VERSION "created by canmatrix"

NS_ :

BS_:

BU_: Boening

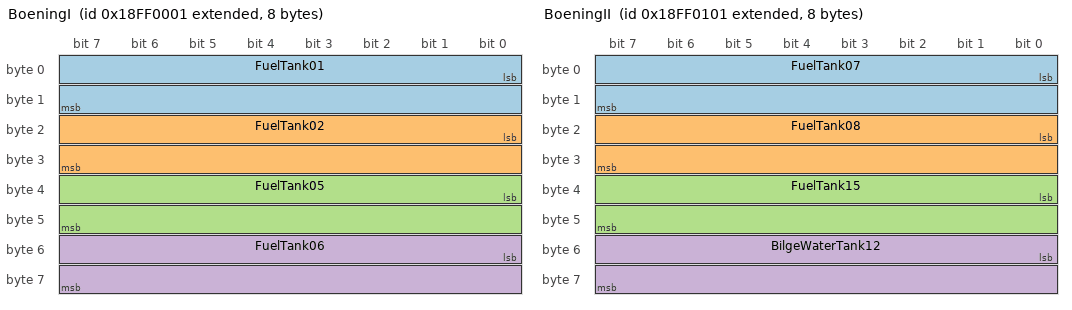
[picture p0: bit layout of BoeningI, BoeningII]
BO_ 2566848513 BoeningI: 8 Vector__XXX
 SG_ FuelTank01 : 0|16@1+ (1,0) [0|65535] "L" Vector__XXX
 SG_ FuelTank02 : 16|16@1+ (1,0) [0|65535] "L" Vector__XXX
 SG_ FuelTank05 : 32|16@1+ (1,0) [0|65535] "L" Vector__XXX
 SG_ FuelTank06 : 48|16@1+ (1,0) [0|65535] "L" Vector__XXX

BO_ 2566848769 BoeningII: 8 Vector__XXX
 SG_ FuelTank07 : 0|16@1+ (1,0) [0|65535] "L" Vector__XXX
 SG_ FuelTank08 : 16|16@1+ (1,0) [0|65535] "L" Vector__XXX
 SG_ FuelTank15 : 32|16@1+ (1,0) [0|65535] "L" Vector__XXX
 SG_ BilgeWaterTank12 : 48|16@1+ (1,0) [0|65535] "L" Vector__XXX

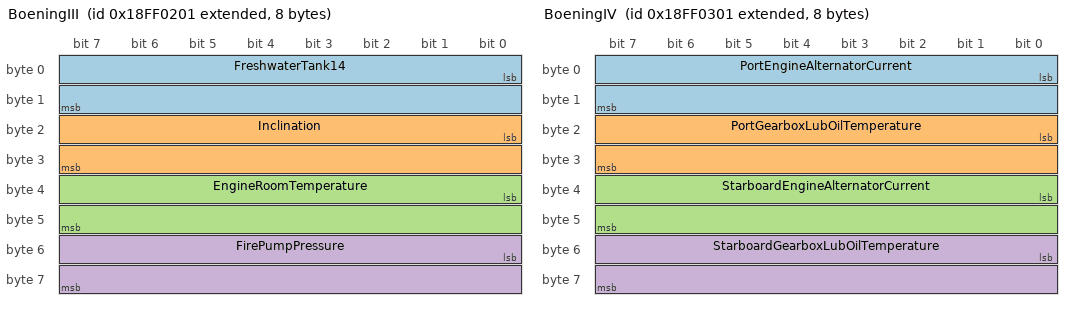
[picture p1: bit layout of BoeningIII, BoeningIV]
BO_ 2566849025 BoeningIII: 8 Vector__XXX
 SG_ FreshwaterTank14 : 0|16@1+ (1,0) [0|65535] "L" Vector__XXX
 SG_ Inclination : 16|16@1- (1,0) [-32768|32767] "grad" Vector__XXX
 SG_ EngineRoomTemperature : 32|16@1+ (1,0) [0|65535] "grad Celsius" Vector__XXX
 SG_ FirePumpPressure : 48|16@1+ (0.1,0) [0|6553.5] "bar" Vector__XXX

BO_ 2566849281 BoeningIV: 8 Vector__XXX
 SG_ PortEngineAlternatorCurrent : 0|16@1+ (1,0) [0|65535] "A" Vector__XXX
 SG_ PortGearboxLubOilTemperature : 16|16@1+ (1,0) [0|65535] "grad Celsius" Vector__XXX
 SG_ StarboardEngineAlternatorCurrent : 32|16@1+ (1,0) [0|65535] "A" Vector__XXX
 SG_ StarboardGearboxLubOilTemperature : 48|16@1+ (1,0) [0|65535] "grad Celsius" Vector__XXX

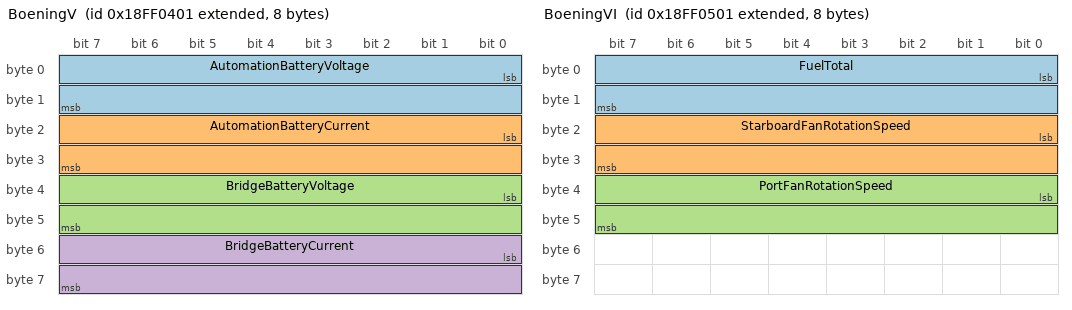
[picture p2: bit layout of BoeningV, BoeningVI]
BO_ 2566849537 BoeningV: 8 Vector__XXX
 SG_ AutomationBatteryVoltage : 0|16@1- (0.1,0) [-3276.8|3276.7] "V" Vector__XXX
 SG_ AutomationBatteryCurrent : 16|16@1- (0.1,0) [-3276.8|3276.7] "A" Vector__XXX
 SG_ BridgeBatteryVoltage : 32|16@1- (0.1,0) [-3276.8|3276.7] "V" Vector__XXX
 SG_ BridgeBatteryCurrent : 48|16@1- (0.1,0) [-3276.8|3276.7] "A" Vector__XXX

BO_ 2566849793 BoeningVI: 8 Vector__XXX
 SG_ FuelTotal : 0|16@1+ (1,0) [0|65535] "L" Vector__XXX
 SG_ StarboardFanRotationSpeed : 16|16@1+ (1,0) [0|65535] "1/min" Vector__XXX
 SG_ PortFanRotationSpeed : 32|16@1+ (1,0) [0|65535] "%" Vector__XXX

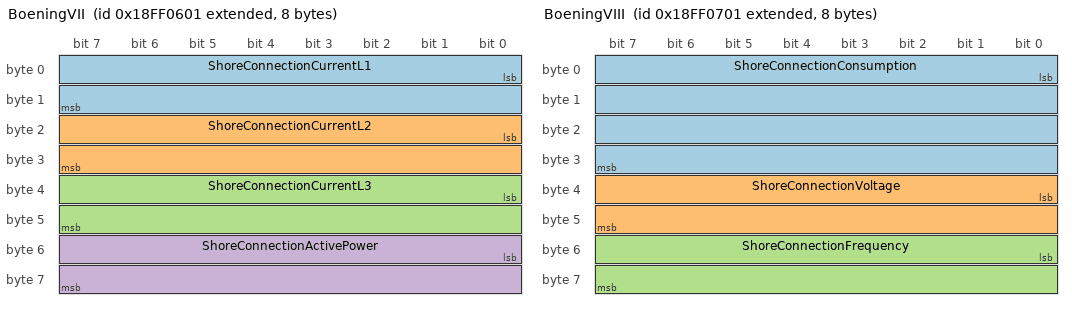
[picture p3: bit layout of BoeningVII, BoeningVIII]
BO_ 2566850049 BoeningVII: 8 Vector__XXX
 SG_ ShoreConnectionCurrentL1 : 0|16@1+ (0.1,0) [0|6553.5] "A" Vector__XXX
 SG_ ShoreConnectionCurrentL2 : 16|16@1+ (0.1,0) [0|6553.5] "A" Vector__XXX
 SG_ ShoreConnectionCurrentL3 : 32|16@1+ (0.1,0) [0|6553.5] "A" Vector__XXX
 SG_ ShoreConnectionActivePower : 48|16@1+ (1,0) [0|65535] "kW" Vector__XXX

BO_ 2566850305 BoeningVIII: 8 Vector__XXX
 SG_ ShoreConnectionConsumption : 0|32@1+ (1,0) [0|4294967295] "kWh" Vector__XXX
 SG_ ShoreConnectionVoltage : 32|16@1+ (1,0) [0|65535] "V" Vector__XXX
 SG_ ShoreConnectionFrequency : 48|16@1+ (0.1,0) [0|6553.5] "Hz" Vector__XXX

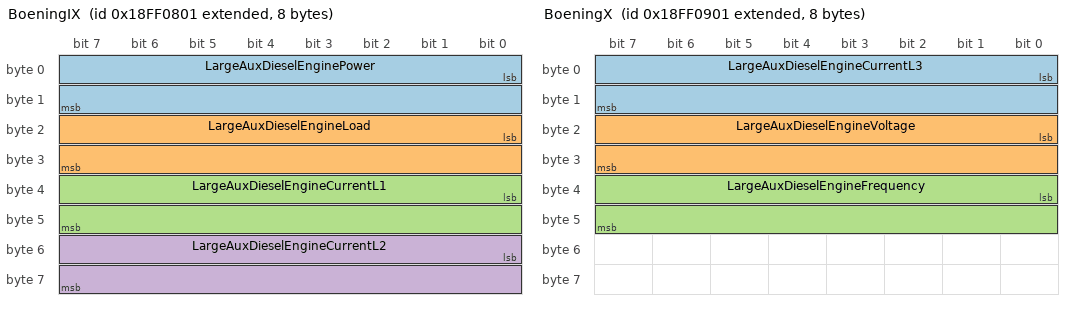
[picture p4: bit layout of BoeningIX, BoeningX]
BO_ 2566850561 BoeningIX: 8 Vector__XXX
 SG_ LargeAuxDieselEnginePower : 0|16@1+ (1,0) [0|65535] "kW" Vector__XXX
 SG_ LargeAuxDieselEngineLoad : 16|16@1+ (1,0) [0|65535] "%" Vector__XXX
 SG_ LargeAuxDieselEngineCurrentL1 : 32|16@1+ (0.1,0) [0|6553.5] "A" Vector__XXX
 SG_ LargeAuxDieselEngineCurrentL2 : 48|16@1+ (0.1,0) [0|6553.5] "A" Vector__XXX

BO_ 2566850817 BoeningX: 8 Vector__XXX
 SG_ LargeAuxDieselEngineCurrentL3 : 0|16@1+ (0.1,0) [0|6553.5] "A" Vector__XXX
 SG_ LargeAuxDieselEngineVoltage : 16|16@1+ (1,0) [0|65535] "V" Vector__XXX
 SG_ LargeAuxDieselEngineFrequency : 32|16@1+ (0.1,0) [0|6553.5] "Hz" Vector__XXX

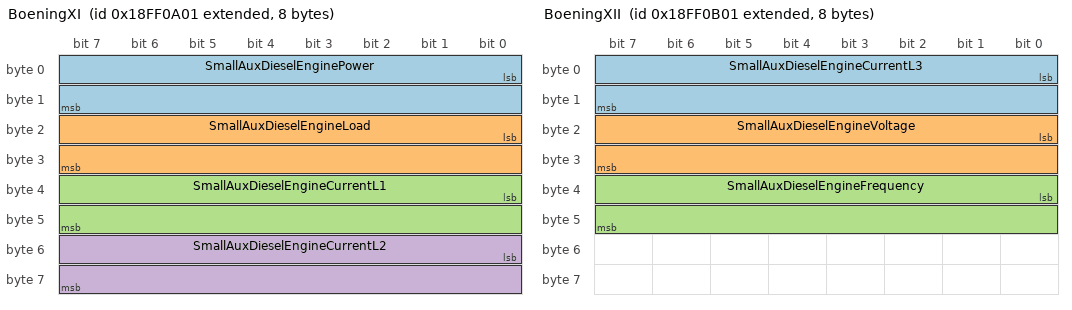
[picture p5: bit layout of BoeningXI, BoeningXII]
BO_ 2566851073 BoeningXI: 8 Vector__XXX
 SG_ SmallAuxDieselEnginePower : 0|16@1+ (1,0) [0|65535] "kW" Vector__XXX
 SG_ SmallAuxDieselEngineLoad : 16|16@1+ (1,0) [0|65535] "%" Vector__XXX
 SG_ SmallAuxDieselEngineCurrentL1 : 32|16@1+ (0.1,0) [0|6553.5] "A" Vector__XXX
 SG_ SmallAuxDieselEngineCurrentL2 : 48|16@1+ (0.1,0) [0|6553.5] "A" Vector__XXX

BO_ 2566851329 BoeningXII: 8 Vector__XXX
 SG_ SmallAuxDieselEngineCurrentL3 : 0|16@1+ (0.1,0) [0|6553.5] "A" Vector__XXX
 SG_ SmallAuxDieselEngineVoltage : 16|16@1+ (1,0) [0|65535] "V" Vector__XXX
 SG_ SmallAuxDieselEngineFrequency : 32|16@1+ (0.1,0) [0|6553.5] "Hz" Vector__XXX

BO_ 2566851585 BoeningXIII: 8 Vector__XXX
 SG_ SmallAuxDieselEngineLubOilPressure : 0|16@1+ (0.1,0) [0|6553.5] "bar" Vector__XXX
 SG_ SmallAuxDieselEngineCoolWaterTemperature : 16|16@1+ (1,0) [0|65535] "grad Celsius" Vector__XXX

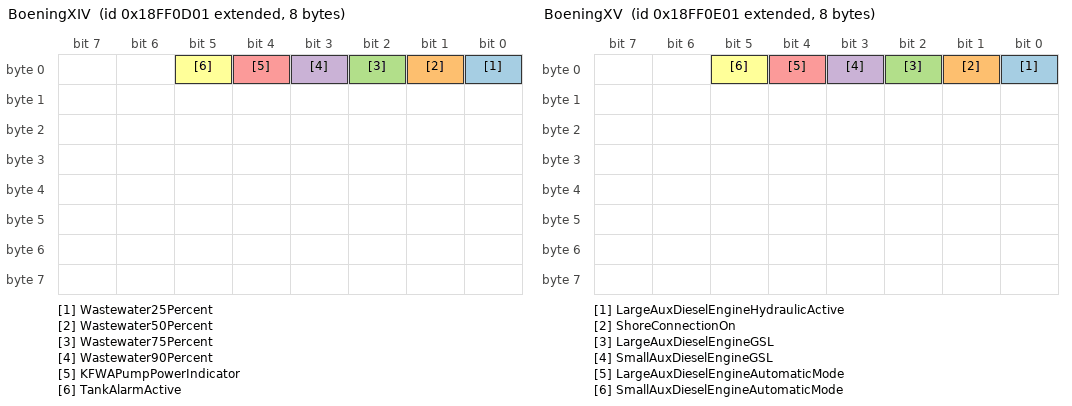
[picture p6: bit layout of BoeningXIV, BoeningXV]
BO_ 2566851841 BoeningXIV: 8 Vector__XXX
 SG_ Wastewater25Percent : 0|1@1+ (1,0) [0|1] "aus/an" Vector__XXX
 SG_ Wastewater50Percent : 1|1@1+ (1,0) [0|1] "aus/an" Vector__XXX
 SG_ Wastewater75Percent : 2|1@1+ (1,0) [0|1] "aus/an" Vector__XXX
 SG_ Wastewater90Percent : 3|1@1+ (1,0) [0|1] "aus/an" Vector__XXX
 SG_ KFWAPumpPowerIndicator : 4|1@1+ (1,0) [0|1] "aus/an" Vector__XXX
 SG_ TankAlarmActive : 5|1@1+ (1,0) [0|1] "aus/an" Vector__XXX

BO_ 2566852097 BoeningXV: 8 Vector__XXX
 SG_ LargeAuxDieselEngineHydraulicActive : 0|1@1+ (1,0) [0|1] "aus/an" Vector__XXX
 SG_ ShoreConnectionOn : 1|1@1+ (1,0) [0|1] "aus/an" Vector__XXX
 SG_ LargeAuxDieselEngineGSL : 2|1@1+ (1,0) [0|1] "aus/an" Vector__XXX
 SG_ SmallAuxDieselEngineGSL : 3|1@1+ (1,0) [0|1] "aus/an" Vector__XXX
 SG_ LargeAuxDieselEngineAutomaticMode : 4|1@1+ (1,0) [0|1] "aus/an" Vector__XXX
 SG_ SmallAuxDieselEngineAutomaticMode : 5|1@1+ (1,0) [0|1] "aus/an" Vector__XXX

CM_ SG_ 2566848513 FuelTank01 "Fuel Tank 01 - Port";
CM_ SG_ 2566848513 FuelTank02 "Fuel Tank 02 - Starboard";
CM_ SG_ 2566848513 FuelTank05 "Fuel Tank 05 - Port";
CM_ SG_ 2566848513 FuelTank06 "Fuel Tank 06 - Starboard";
CM_ SG_ 2566848769 FuelTank07 "Fuel Tank 07 - Port";
CM_ SG_ 2566848769 FuelTank08 "Fuel Tank 08 - Starboard";
CM_ SG_ 2566848769 FuelTank15 "Fuel Tank 15 - Middle";
CM_ SG_ 2566848769 BilgeWaterTank12 "Bilge Water Tank 12";
CM_ SG_ 2566849025 FreshwaterTank14 "Freshwater Tank 14";
CM_ SG_ 2566849025 Inclination "Inclination";
CM_ SG_ 2566849025 EngineRoomTemperature "Engine Room Temperature";
CM_ SG_ 2566849025 FirePumpPressure "Fire Pump Pressure";
CM_ SG_ 2566849281 PortEngineAlternatorCurrent "Port Engine Alternator Current";
CM_ SG_ 2566849281 PortGearboxLubOilTemperature "Port Gearbox Lubrication Oil Temperature";
CM_ SG_ 2566849281 StarboardEngineAlternatorCurrent "Starboard Engine Alternator Current";
CM_ SG_ 2566849281 StarboardGearboxLubOilTemperature "Starboard Gearbox Lubrication Oil Temperature";
CM_ SG_ 2566849537 AutomationBatteryVoltage "Automation Battery Voltage";
CM_ SG_ 2566849537 AutomationBatteryCurrent "Automation Battery Current";
CM_ SG_ 2566849537 BridgeBatteryVoltage "Bridge Battery Voltage";
CM_ SG_ 2566849537 BridgeBatteryCurrent "Bridge Battery Current";
CM_ SG_ 2566849793 FuelTotal "Fuel Total";
CM_ SG_ 2566849793 StarboardFanRotationSpeed "Starboard Fan Rotation Speed";
CM_ SG_ 2566849793 PortFanRotationSpeed "Port Fan Rotation Speed";
CM_ SG_ 2566850049 ShoreConnectionCurrentL1 "Shore Connection Current L1";
CM_ SG_ 2566850049 ShoreConnectionCurrentL2 "Shore Connection Current L2";
CM_ SG_ 2566850049 ShoreConnectionCurrentL3 "Shore Connection Current L3";
CM_ SG_ 2566850049 ShoreConnectionActivePower "Shore Connection Active Power";
CM_ SG_ 2566850305 ShoreConnectionConsumption "Shore Connection Consumption";
CM_ SG_ 2566850305 ShoreConnectionVoltage "Shore Connection Voltage";
CM_ SG_ 2566850305 ShoreConnectionFrequency "Shore Connection Frequency";
CM_ SG_ 2566850561 LargeAuxDieselEnginePower "Large Auxiliary Diesel Engine Power";
CM_ SG_ 2566850561 LargeAuxDieselEngineLoad "Large Auxiliary Diesel Engine Load";
CM_ SG_ 2566850561 LargeAuxDieselEngineCurrentL1 "Large Auxiliary Diesel Engine Current L1";
CM_ SG_ 2566850561 LargeAuxDieselEngineCurrentL2 "Large Auxiliary Diesel Engine Current L2";
CM_ SG_ 2566850817 LargeAuxDieselEngineCurrentL3 "Large Auxiliary Diesel Engine Current L3";
CM_ SG_ 2566850817 LargeAuxDieselEngineVoltage "Large Auxiliary Diesel Engine Voltage";
CM_ SG_ 2566850817 LargeAuxDieselEngineFrequency "Large Auxiliary Diesel Engine Frequency";
CM_ SG_ 2566851073 SmallAuxDieselEnginePower "Small Auxiliary Diesel Engine Power";
CM_ SG_ 2566851073 SmallAuxDieselEngineLoad "Small Auxiliary Diesel Engine Load";
CM_ SG_ 2566851073 SmallAuxDieselEngineCurrentL1 "Small Auxiliary Diesel Engine Current L1";
CM_ SG_ 2566851073 SmallAuxDieselEngineCurrentL2 "Small Auxiliary Diesel Engine Current L2";
CM_ SG_ 2566851329 SmallAuxDieselEngineCurrentL3 "Small Auxiliary Diesel Engine Current L3";
CM_ SG_ 2566851329 SmallAuxDieselEngineVoltage "Small Auxiliary Diesel Engine Voltage";
CM_ SG_ 2566851329 SmallAuxDieselEngineFrequency "Small Auxiliary Diesel Engine Frequency";
CM_ SG_ 2566851585 SmallAuxDieselEngineLubOilPressure "Small Auxiliary Diesel Engine Lubrication Oil Pressure";
CM_ SG_ 2566851585 SmallAuxDieselEngineCoolWaterTemperature "Small Auxiliary Diesel Engine Cool Water Temperature";
CM_ SG_ 2566851841 Wastewater25Percent "Wastewater 25%";
CM_ SG_ 2566851841 Wastewater50Percent "Wastewater 50%";
CM_ SG_ 2566851841 Wastewater75Percent "Wastewater 75%";
CM_ SG_ 2566851841 Wastewater90Percent "Wastewater 90%";
CM_ SG_ 2566851841 KFWAPumpPowerIndicator "KFWA Pump Power Indicator";
CM_ SG_ 2566851841 TankAlarmActive "Tank Alarm Active";
CM_ SG_ 2566852097 LargeAuxDieselEngineHydraulicActive "Large Auxiliary Diesel Engine Hydraulic Active";
CM_ SG_ 2566852097 ShoreConnectionOn "Shore Connection On";
CM_ SG_ 2566852097 LargeAuxDieselEngineGSL "Large Auxiliary Diesel Engine GSL";
CM_ SG_ 2566852097 SmallAuxDieselEngineGSL "Small Auxiliary Diesel Engine GSL";
CM_ SG_ 2566852097 LargeAuxDieselEngineAutomaticMode "Large Auxiliary Diesel Engine Automatic Mode";
CM_ SG_ 2566852097 SmallAuxDieselEngineAutomaticMode "Small Auxiliary Diesel Engine Automatic Mode";
